# or1200_top: IP-XACT component
VLNV opencores.org:or1k:or1200_top:1300.008

## Address spaces and blocks
Sys_Group.Sys_Block: base 0x0, range 0x800, width 32
DC_Group.DC_Block: base 0x1800, range 0x800, width 16
PIC_Group.PIC_Block: base 0x4800, range 0x800, width 16

## Registers
Registers are 32-bit, read-only, no defined reset value unless marked. A register's access mark holds for its fields unless they carry their own. Offsets are from the block's base; lines under a group give offsets from that group; [hi:lo] are bit positions; {n}, {i} and the like mark numbered series; 'fields as' and 'values as' point back to an identical list; <NAME> marks a mode.

## Sys_Group.Sys_Block
Base 0x00000000
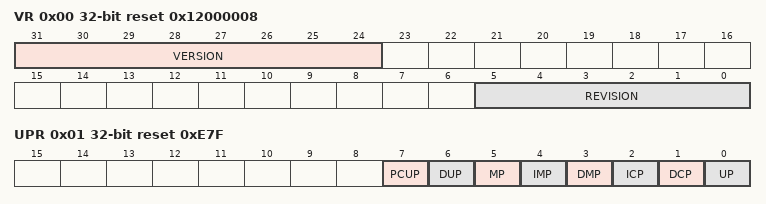
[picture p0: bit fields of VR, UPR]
0x00 VR reset 0x12000008
  [31:24] VERSION, [5:0] REVISION
0x01 UPR reset 0xE7F — Unit Present Register
  [7] PCUP, [6] DUP, [5] MP, [4] IMP, [3] DMP, [2] ICP, [1] DCP, [0] UP
0x10 NPC rw — Next Program Counter Register
  [31:0] PC

## DC_Group.DC_Block
Base 0x00001800
0x02 DCBFR wo
  [0] FLUSH
0x03 DCBIR wo
  [0] INVALIDATE

## PIC_Group.PIC_Block
Base 0x00004800
0x00 PICMR access not given reset 0x0 (reset mask 0x3FFF)
  [18:2] MASK
